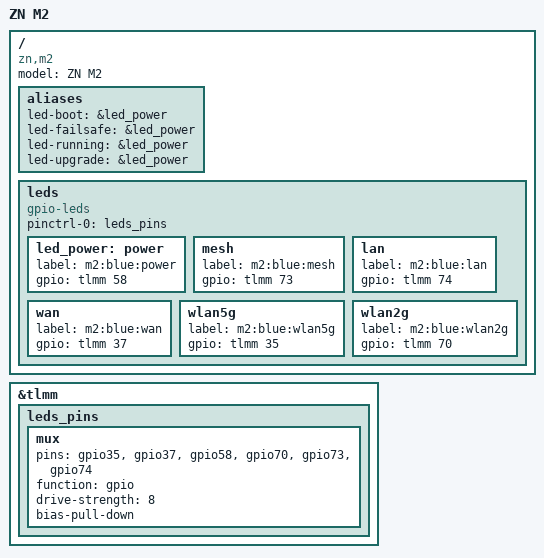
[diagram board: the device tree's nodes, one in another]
// SPDX-License-Identifier: (GPL-2.0+)

/dts-v1/;

#include "ipq6018-cmiot.dtsi"

/ {
	model = "ZN M2";
	compatible = "zn,m2", "qcom,ipq6018";

	aliases {
 		led-boot = &led_power;
 		led-failsafe = &led_power;
 		led-running = &led_power;
 		led-upgrade = &led_power;
	};

	leds {
		compatible = "gpio-leds";
		pinctrl-0 = <&leds_pins>;
		pinctrl-names = "default";

		led_power: power {
			label = "m2:blue:power";
			gpio = <&tlmm 58 GPIO_ACTIVE_HIGH>;
		};

		mesh {
			label = "m2:blue:mesh";
			gpio = <&tlmm 73 GPIO_ACTIVE_HIGH>;
		};

		lan {
			label = "m2:blue:lan";
			gpio = <&tlmm 74 GPIO_ACTIVE_HIGH>;
		};

		wan {
			label = "m2:blue:wan";
			gpio = <&tlmm 37 GPIO_ACTIVE_HIGH>;
		};

		wlan5g {
			label = "m2:blue:wlan5g";
			gpio = <&tlmm 35 GPIO_ACTIVE_HIGH>;
		};

		wlan2g {
			label = "m2:blue:wlan2g";
			gpio = <&tlmm 70 GPIO_ACTIVE_HIGH>;
		};
	};
};

&tlmm {
	leds_pins: leds_pins {
		mux {
			pins = "gpio35", "gpio37",
				"gpio58", "gpio70",
				"gpio73", "gpio74";
			function = "gpio";
			drive-strength = <8>;
			bias-pull-down;
		};
	};
};
